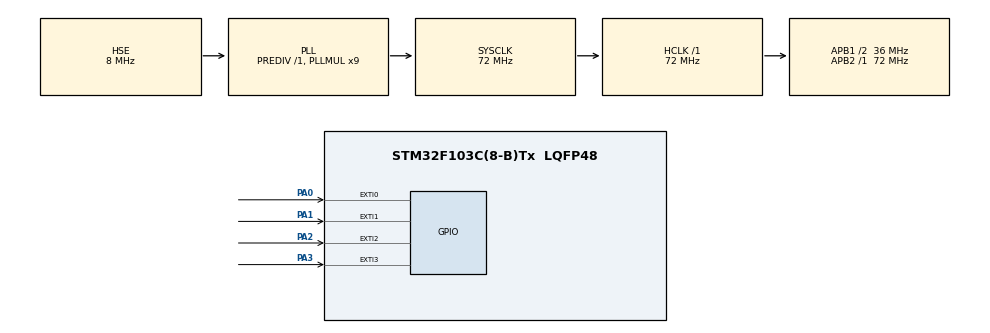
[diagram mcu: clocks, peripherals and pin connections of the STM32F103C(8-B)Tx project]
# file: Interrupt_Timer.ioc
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Mcu.Family=STM32F1
Mcu.Name=STM32F103C(8-B)Tx
Mcu.Package=LQFP48
NVIC.EXTI0_IRQn=true\:0\:0\:false\:false\:true\:true\:true\:true
NVIC.EXTI1_IRQn=true\:0\:0\:false\:false\:true\:true\:true\:true
NVIC.EXTI2_IRQn=true\:0\:0\:false\:false\:true\:true\:true\:true
NVIC.EXTI3_IRQn=true\:0\:0\:false\:false\:true\:true\:true\:true
NVIC.PriorityGroup=NVIC_PRIORITYGROUP_4
NVIC.TIM3_IRQn=true\:0\:0\:false\:false\:true\:true\:true\:true
PA0-WKUP.Signal=GPXTI0
PA1.Signal=GPXTI1
PA13.Mode=Serial_Wire
PA13.Signal=SYS_JTMS-SWDIO
PA14.Mode=Serial_Wire
PA14.Signal=SYS_JTCK-SWCLK
PA2.Signal=GPXTI2
PA3.Signal=GPXTI3
PD0-OSC_IN.Mode=HSE-External-Oscillator
PD0-OSC_IN.Signal=RCC_OSC_IN
PD1-OSC_OUT.Mode=HSE-External-Oscillator
PD1-OSC_OUT.Signal=RCC_OSC_OUT
ProjectManager.HeapSize=0x200
ProjectManager.StackSize=0x400
ProjectManager.TargetToolchain=STM32CubeIDE
RCC.AHBFreq_Value=72000000
RCC.APB1CLKDivider=RCC_HCLK_DIV2
RCC.APB1Freq_Value=36000000
RCC.APB1TimFreq_Value=72000000
RCC.APB2Freq_Value=72000000
RCC.APB2TimFreq_Value=72000000
RCC.HCLKFreq_Value=72000000
RCC.PLLMUL=RCC_PLL_MUL9
RCC.PLLSourceVirtual=RCC_PLLSOURCE_HSE
RCC.SYSCLKFreq_VALUE=72000000
RCC.SYSCLKSource=RCC_SYSCLKSOURCE_PLLCLK
RCC.USBFreq_Value=72000000
TIM3.Prescaler=71
VP_TIM3_VS_ClockSourceINT.Mode=Internal
board=custom

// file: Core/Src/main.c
/* USER CODE BEGIN Header */
/**
  ******************************************************************************
  * @file           : main.c
  * @brief          : Main program body
  ******************************************************************************
  * @attention
  *
  * Copyright (c) 2022 STMicroelectronics.
  * All rights reserved.
  *
  * This software is licensed under terms that can be found in the LICENSE file
  * in the root directory of this software component.
  * If no LICENSE file comes with this software, it is provided AS-IS.
  *
  ******************************************************************************
  */
/* USER CODE END Header */
#include "main.h"

 TIM_HandleTypeDef htim3;

void SystemClock_Config(void);
static void MX_GPIO_Init(void);
static void MX_TIM3_Init(void);

/* USER CODE BEGIN 0 */
extern int32_t HighPulse[7];
extern int32_t LowPulse[7];
/* USER CODE END 0 */

int main(void)
{

  /* MCU Configuration--------------------------------------------------------*/

  /* Reset of all peripherals, Initializes the Flash interface and the Systick. */
  HAL_Init();

  /* Configure the system clock */
  SystemClock_Config();

  /* Initialize all configured peripherals */
  MX_GPIO_Init();
  MX_TIM3_Init();
  /* USER CODE BEGIN 2 */
  /*Enable Timer*/
  __HAL_TIM_ENABLE(&htim3);
  /* Clear the IT pending Bit */
  __HAL_TIM_CLEAR_IT(&htim3, TIM_IT_UPDATE);
  /* Disable the TIM Update interrupt */
  __HAL_TIM_DISABLE_IT(&htim3, TIM_IT_UPDATE);
  /* USER CODE END 2 */

  /* Infinite loop */
  while (1)
  {

  }
}

void SystemClock_Config(void)
{
  RCC_OscInitTypeDef RCC_OscInitStruct = {0};
  RCC_ClkInitTypeDef RCC_ClkInitStruct = {0};

  /** Initializes the RCC Oscillators according to the specified parameters
  * in the RCC_OscInitTypeDef structure.
  */
  RCC_OscInitStruct.OscillatorType = RCC_OSCILLATORTYPE_HSE;
  RCC_OscInitStruct.HSEState = RCC_HSE_ON;
  RCC_OscInitStruct.HSEPredivValue = RCC_HSE_PREDIV_DIV1;
  RCC_OscInitStruct.HSIState = RCC_HSI_ON;
  RCC_OscInitStruct.PLL.PLLState = RCC_PLL_ON;
  RCC_OscInitStruct.PLL.PLLSource = RCC_PLLSOURCE_HSE;
  RCC_OscInitStruct.PLL.PLLMUL = RCC_PLL_MUL9;
  if (HAL_RCC_OscConfig(&RCC_OscInitStruct) != HAL_OK)
  {
    Error_Handler();
  }

  /** Initializes the CPU, AHB and APB buses clocks
  */
  RCC_ClkInitStruct.ClockType = RCC_CLOCKTYPE_HCLK|RCC_CLOCKTYPE_SYSCLK
                              |RCC_CLOCKTYPE_PCLK1|RCC_CLOCKTYPE_PCLK2;
  RCC_ClkInitStruct.SYSCLKSource = RCC_SYSCLKSOURCE_PLLCLK;
  RCC_ClkInitStruct.AHBCLKDivider = RCC_SYSCLK_DIV1;
  RCC_ClkInitStruct.APB1CLKDivider = RCC_HCLK_DIV2;
  RCC_ClkInitStruct.APB2CLKDivider = RCC_HCLK_DIV1;

  if (HAL_RCC_ClockConfig(&RCC_ClkInitStruct, FLASH_LATENCY_2) != HAL_OK)
  {
    Error_Handler();
  }
}

static void MX_TIM3_Init(void)
{

  TIM_ClockConfigTypeDef sClockSourceConfig = {0};
  TIM_MasterConfigTypeDef sMasterConfig = {0};

  htim3.Instance = TIM3;
  htim3.Init.Prescaler = 71;
  htim3.Init.CounterMode = TIM_COUNTERMODE_UP;
  htim3.Init.Period = 65535;
  htim3.Init.ClockDivision = TIM_CLOCKDIVISION_DIV1;
  htim3.Init.AutoReloadPreload = TIM_AUTORELOAD_PRELOAD_DISABLE;
  if (HAL_TIM_Base_Init(&htim3) != HAL_OK)
  {
    Error_Handler();
  }
  sClockSourceConfig.ClockSource = TIM_CLOCKSOURCE_INTERNAL;
  if (HAL_TIM_ConfigClockSource(&htim3, &sClockSourceConfig) != HAL_OK)
  {
    Error_Handler();
  }
  sMasterConfig.MasterOutputTrigger = TIM_TRGO_RESET;
  sMasterConfig.MasterSlaveMode = TIM_MASTERSLAVEMODE_DISABLE;
  if (HAL_TIMEx_MasterConfigSynchronization(&htim3, &sMasterConfig) != HAL_OK)
  {
    Error_Handler();
  }

}

static void MX_GPIO_Init(void)
{
  GPIO_InitTypeDef GPIO_InitStruct = {0};

  /* GPIO Ports Clock Enable */
  __HAL_RCC_GPIOD_CLK_ENABLE();
  __HAL_RCC_GPIOA_CLK_ENABLE();

  /*Configure GPIO pins : PA0 PA1 PA2 PA3 */
  GPIO_InitStruct.Pin = GPIO_PIN_0|GPIO_PIN_1|GPIO_PIN_2|GPIO_PIN_3;
  GPIO_InitStruct.Mode = GPIO_MODE_IT_RISING;
  GPIO_InitStruct.Pull = GPIO_NOPULL;
  HAL_GPIO_Init(GPIOA, &GPIO_InitStruct);

  /* EXTI interrupt init*/
  HAL_NVIC_SetPriority(EXTI0_IRQn, 0, 0);
  HAL_NVIC_EnableIRQ(EXTI0_IRQn);

  HAL_NVIC_SetPriority(EXTI1_IRQn, 0, 0);
  HAL_NVIC_EnableIRQ(EXTI1_IRQn);

  HAL_NVIC_SetPriority(EXTI2_IRQn, 0, 0);
  HAL_NVIC_EnableIRQ(EXTI2_IRQn);

  HAL_NVIC_SetPriority(EXTI3_IRQn, 0, 0);
  HAL_NVIC_EnableIRQ(EXTI3_IRQn);

}

void Error_Handler(void)
{
  __disable_irq();
  while (1)
  {
  }
}
